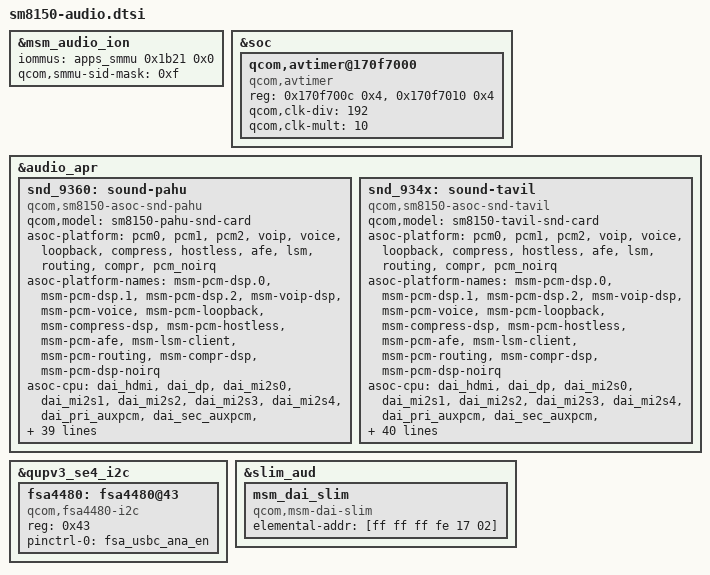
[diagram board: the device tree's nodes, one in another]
/* Copyright (c) 2018, The Linux Foundation. All rights reserved.
 *
 * This program is free software; you can redistribute it and/or modify
 * it under the terms of the GNU General Public License version 2 and
 * only version 2 as published by the Free Software Foundation.
 *
 * This program is distributed in the hope that it will be useful,
 * but WITHOUT ANY WARRANTY; without even the implied warranty of
 * MERCHANTABILITY or FITNESS FOR A PARTICULAR PURPOSE.  See the
 * GNU General Public License for more details.
 */

#include "msm-audio-lpass.dtsi"

&msm_audio_ion {
	iommus = <&apps_smmu 0x1b21 0x0>;
	qcom,smmu-sid-mask = /bits/ 64 <0xf>;
};

&soc {
	qcom,avtimer@170f7000 {
		compatible = "qcom,avtimer";
		reg = <0x170f700c 0x4>,
		      <0x170f7010 0x4>;
		reg-names = "avtimer_lsb_addr", "avtimer_msb_addr";
		qcom,clk-div = <192>;
		qcom,clk-mult = <10>;
	};
};

&audio_apr {
	snd_9360: sound-pahu {
		compatible = "qcom,sm8150-asoc-snd-pahu";
		qcom,model = "sm8150-pahu-snd-card";

		asoc-platform = <&pcm0>, <&pcm1>, <&pcm2>, <&voip>, <&voice>,
				<&loopback>, <&compress>, <&hostless>,
				<&afe>, <&lsm>, <&routing>, <&compr>,
				<&pcm_noirq>;
		asoc-platform-names = "msm-pcm-dsp.0", "msm-pcm-dsp.1",
				"msm-pcm-dsp.2", "msm-voip-dsp",
				"msm-pcm-voice", "msm-pcm-loopback",
				"msm-compress-dsp", "msm-pcm-hostless",
				"msm-pcm-afe", "msm-lsm-client",
				"msm-pcm-routing", "msm-compr-dsp",
				"msm-pcm-dsp-noirq";
		asoc-cpu = <&dai_hdmi>, <&dai_dp>,
				<&dai_mi2s0>, <&dai_mi2s1>,
				<&dai_mi2s2>, <&dai_mi2s3>,
				<&dai_mi2s4>, <&dai_pri_auxpcm>,
				<&dai_sec_auxpcm>, <&dai_tert_auxpcm>,
				<&dai_quat_auxpcm>, <&dai_quin_auxpcm>,
				<&sb_0_rx>, <&sb_0_tx>, <&sb_1_rx>, <&sb_1_tx>,
				<&sb_2_rx>, <&sb_2_tx>, <&sb_3_rx>, <&sb_3_tx>,
				<&sb_4_rx>, <&sb_4_tx>, <&sb_5_tx>,
				<&afe_pcm_rx>, <&afe_pcm_tx>, <&afe_proxy_rx>,
				<&afe_proxy_tx>, <&incall_record_rx>,
				<&incall_record_tx>, <&incall_music_rx>,
				<&incall_music_2_rx>, <&sb_5_rx>, <&sb_6_rx>,
				<&sb_7_rx>, <&sb_7_tx>, <&sb_8_tx>,
				<&usb_audio_rx>, <&usb_audio_tx>,
				<&dai_pri_tdm_rx_0>, <&dai_pri_tdm_tx_0>,
				<&dai_sec_tdm_rx_0>, <&dai_sec_tdm_tx_0>,
				<&dai_tert_tdm_rx_0>, <&dai_tert_tdm_tx_0>,
				<&dai_quat_tdm_rx_0>, <&dai_quat_tdm_tx_0>,
				<&dai_quin_tdm_rx_0>, <&dai_quin_tdm_tx_0>;
		asoc-cpu-names = "msm-dai-q6-hdmi.8",  "msm-dai-q6-dp.24608",
				"msm-dai-q6-mi2s.0", "msm-dai-q6-mi2s.1",
				"msm-dai-q6-mi2s.2", "msm-dai-q6-mi2s.3",
				"msm-dai-q6-mi2s.4", "msm-dai-q6-auxpcm.1",
				"msm-dai-q6-auxpcm.2", "msm-dai-q6-auxpcm.3",
				"msm-dai-q6-auxpcm.4", "msm-dai-q6-auxpcm.5",
				"msm-dai-q6-dev.16384", "msm-dai-q6-dev.16385",
				"msm-dai-q6-dev.16386", "msm-dai-q6-dev.16387",
				"msm-dai-q6-dev.16388", "msm-dai-q6-dev.16389",
				"msm-dai-q6-dev.16390", "msm-dai-q6-dev.16391",
				"msm-dai-q6-dev.16392", "msm-dai-q6-dev.16393",
				"msm-dai-q6-dev.16395", "msm-dai-q6-dev.224",
				"msm-dai-q6-dev.225", "msm-dai-q6-dev.241",
				"msm-dai-q6-dev.240", "msm-dai-q6-dev.32771",
				"msm-dai-q6-dev.32772", "msm-dai-q6-dev.32773",
				"msm-dai-q6-dev.32770", "msm-dai-q6-dev.16394",
				"msm-dai-q6-dev.16396", "msm-dai-q6-dev.16398",
				"msm-dai-q6-dev.16399", "msm-dai-q6-dev.16401",
				"msm-dai-q6-dev.28672", "msm-dai-q6-dev.28673",
				"msm-dai-q6-tdm.36864", "msm-dai-q6-tdm.36865",
				"msm-dai-q6-tdm.36880", "msm-dai-q6-tdm.36881",
				"msm-dai-q6-tdm.36896", "msm-dai-q6-tdm.36897",
				"msm-dai-q6-tdm.36912", "msm-dai-q6-tdm.36913",
				"msm-dai-q6-tdm.36928", "msm-dai-q6-tdm.36929";
	};

	snd_934x: sound-tavil {
		compatible = "qcom,sm8150-asoc-snd-tavil";
		qcom,model = "sm8150-tavil-snd-card";

		asoc-platform = <&pcm0>, <&pcm1>, <&pcm2>, <&voip>, <&voice>,
				<&loopback>, <&compress>, <&hostless>,
				<&afe>, <&lsm>, <&routing>, <&compr>,
				<&pcm_noirq>;
		asoc-platform-names = "msm-pcm-dsp.0", "msm-pcm-dsp.1",
				"msm-pcm-dsp.2", "msm-voip-dsp",
				"msm-pcm-voice", "msm-pcm-loopback",
				"msm-compress-dsp", "msm-pcm-hostless",
				"msm-pcm-afe", "msm-lsm-client",
				"msm-pcm-routing", "msm-compr-dsp",
				"msm-pcm-dsp-noirq";
		asoc-cpu = <&dai_hdmi>, <&dai_dp>,
				<&dai_mi2s0>, <&dai_mi2s1>,
				<&dai_mi2s2>, <&dai_mi2s3>,
				<&dai_mi2s4>, <&dai_pri_auxpcm>,
				<&dai_sec_auxpcm>, <&dai_tert_auxpcm>,
				<&dai_quat_auxpcm>, <&dai_quin_auxpcm>,
				<&sb_0_rx>, <&sb_0_tx>, <&sb_1_rx>, <&sb_1_tx>,
				<&sb_2_rx>, <&sb_2_tx>, <&sb_3_rx>, <&sb_3_tx>,
				<&sb_4_rx>, <&sb_4_tx>, <&sb_5_tx>,
				<&afe_pcm_rx>, <&afe_pcm_tx>, <&afe_proxy_rx>,
				<&afe_proxy_tx>, <&incall_record_rx>,
				<&incall_record_tx>, <&incall_music_rx>,
				<&incall_music_2_rx>, <&sb_5_rx>, <&sb_6_rx>,
				<&sb_7_rx>, <&sb_7_tx>, <&sb_8_tx>,
				<&usb_audio_rx>, <&usb_audio_tx>,
				<&dai_pri_tdm_rx_0>, <&dai_pri_tdm_tx_0>,
				<&dai_sec_tdm_rx_0>, <&dai_sec_tdm_tx_0>,
				<&dai_tert_tdm_rx_0>, <&dai_tert_tdm_tx_0>,
				<&dai_quat_tdm_rx_0>, <&dai_quat_tdm_tx_0>,
				<&dai_quin_tdm_rx_0>, <&dai_quin_tdm_tx_0>;
		asoc-cpu-names = "msm-dai-q6-hdmi.8",  "msm-dai-q6-dp.24608",
				"msm-dai-q6-mi2s.0", "msm-dai-q6-mi2s.1",
				"msm-dai-q6-mi2s.2", "msm-dai-q6-mi2s.3",
				"msm-dai-q6-mi2s.4", "msm-dai-q6-auxpcm.1",
				"msm-dai-q6-auxpcm.2", "msm-dai-q6-auxpcm.3",
				"msm-dai-q6-auxpcm.4", "msm-dai-q6-auxpcm.5",
				"msm-dai-q6-dev.16384", "msm-dai-q6-dev.16385",
				"msm-dai-q6-dev.16386", "msm-dai-q6-dev.16387",
				"msm-dai-q6-dev.16388", "msm-dai-q6-dev.16389",
				"msm-dai-q6-dev.16390", "msm-dai-q6-dev.16391",
				"msm-dai-q6-dev.16392", "msm-dai-q6-dev.16393",
				"msm-dai-q6-dev.16395", "msm-dai-q6-dev.224",
				"msm-dai-q6-dev.225", "msm-dai-q6-dev.241",
				"msm-dai-q6-dev.240", "msm-dai-q6-dev.32771",
				"msm-dai-q6-dev.32772", "msm-dai-q6-dev.32773",
				"msm-dai-q6-dev.32770", "msm-dai-q6-dev.16394",
				"msm-dai-q6-dev.16396", "msm-dai-q6-dev.16398",
				"msm-dai-q6-dev.16399", "msm-dai-q6-dev.16401",
				"msm-dai-q6-dev.28672", "msm-dai-q6-dev.28673",
				"msm-dai-q6-tdm.36864", "msm-dai-q6-tdm.36865",
				"msm-dai-q6-tdm.36880", "msm-dai-q6-tdm.36881",
				"msm-dai-q6-tdm.36896", "msm-dai-q6-tdm.36897",
				"msm-dai-q6-tdm.36912", "msm-dai-q6-tdm.36913",
				"msm-dai-q6-tdm.36928", "msm-dai-q6-tdm.36929";
		fsa4480-i2c-handle = <&fsa4480>;
	};
};

&qupv3_se4_i2c {
	status = "ok";
	fsa4480: fsa4480@43 {
		compatible = "qcom,fsa4480-i2c";
		reg = <0x43>;
		pinctrl-names = "default";
		pinctrl-0 = <&fsa_usbc_ana_en>;
	};
};

&slim_aud {
	msm_dai_slim {
		compatible = "qcom,msm-dai-slim";
		elemental-addr = [ff ff ff fe 17 02];
	};
};
